# PCIE0_CORE_DBN_CFG_PCIE_CORE register map
Vendor: Texas Instruments
Peripheral module from a debugger description file (folder J722S).
Registers are 32-bit, read-write, reset 0x0 unless marked. A register's access mark holds for its fields unless they carry their own. Offsets are as the file gives them; lines under a group give offsets from that group; [hi:lo] are bit positions; {n}, {i} and the like mark numbered series; 'fields as' and 'values as' point back to an identical list; <NAME> marks a mode.

## PCIE0_CORE_DBN_CFG_PCIE_CORE (part 1 of 6)
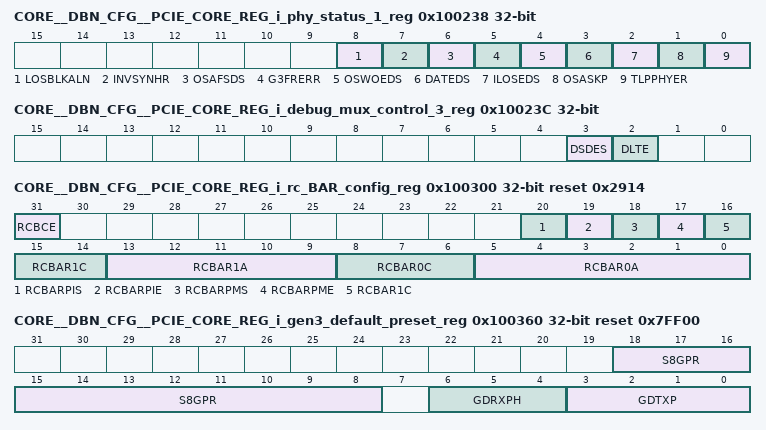
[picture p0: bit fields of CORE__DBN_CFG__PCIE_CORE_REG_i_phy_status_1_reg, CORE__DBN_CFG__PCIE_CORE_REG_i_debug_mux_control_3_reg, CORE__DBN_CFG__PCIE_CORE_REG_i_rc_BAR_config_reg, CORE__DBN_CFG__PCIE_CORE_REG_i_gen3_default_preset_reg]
0x100238 CORE__DBN_CFG__PCIE_CORE_REG_i_phy_status_1_reg access not given — This status register provides additional debug information about the PHY. Bits 8:0 provide information to debug Receiver Errors.
  [8] LOSBLKALN — This bit is set if the PHY Loses Block Alignment during data stream. This is detected based upon an unexpected PIPE_RX_VALID input deassertion during data stream. Write a 1 to clear this error. (access R/W1TC)
  [7] INVSYNHR — This bit is set if an invalid Sync Header is detected. 00 and 11 are Invalid Sync Headers. Write a 1 to clear this error. . (access R/W1TC)
  [6] OSAFSDS — This bit is set if an SDS is received after an SDS. This is a framing error. Write a 1 to clear this error. (access R/W1TC)
  [5] G3FRERR — This bit is set if a framing error is detected while receiving a TLP in Gen3. Example, if an invalid token is received in a data stream, this error is flagged. Write a 1 to clear this error. (access R/W1TC)
  [4] OSWOEDS — This bit is set if an Ordered Set Block is received without an EDS. This is a framing error. Write a 1 to clear this error. (access R/W1TC)
  [3] DATEDS — This bit is set if a Data Block is received after an EDS. Write a 1 to clear this error. (access R/W1TC)
  [2] ILOSEDS — The Valid OS blocks after an EDS are EIOS, EIEOS and SKP. If any other OS blocks are received after EDS, then it is a framing error and this bit is asserted. (access R/W1TC)
  [1] OSASKP — This bit indicates that an Ordered Set BLock was received immediately after a SKIP OS. This is a framing error. Write a 1 to clear this field. (access R/W1TC)
  [0] TLPPHYER — This bit indicates that a PHY Error was detected on the PIPE_RX_STATUS within a TLP. Write a 1 to clear this field. (access R/W1TC)
0x10023C CORE__DBN_CFG__PCIE_CORE_REG_i_debug_mux_control_3_reg
  [3] DSDES — Used to disable and enable Surprise Down Error status logging and by default it is enabled
  [2] DLTE — Used to disable and enable link training error logging and by default it is enabled
0x100300 CORE__DBN_CFG__PCIE_CORE_REG_i_rc_BAR_config_reg reset 0x2914 — The root complex side of the Controller contains two memory BARs that can be used for address-range checking of incoming requests from devices connected to it. The fields in this register determine the configuration of these BARs.
  [31] RCBCE — This bit must be set to 1 to enable BAR checking in the RC mode. When this bit is set to 0, the Controller will forward all incoming memory requests to the client logic without checking their address ranges.
  [20] RCBARPIS — Width of IO Base and Limit registers in type1 config space. 0=32 bits, 1=64bits
  [19] RCBARPIE — Enable for IO Base and Limit registers in type1 config space
  [18] RCBARPMS — Width of Prefetchable Memory Base and Limit registers in type1 config space. 0=32 bits, 1=64bits
  [17] RCBARPME — Enable for Prefetchable memory base and limit registers in type1 config space
  [16:14] RCBAR1C — Specifies the configuration of RC BAR1. The various encodings are: 000: Disabled 001: 32bit IO BAR 010-011: Reserved 100: 32bit memory BAR, non prefetchable 101: 32bit memory BAR, prefetchable 110-111: Reserved
  [13:9] RCBAR1A — This field specifies the aperture of the RC BAR 1. The encodings are: 0000 = 4, 00001 =8B,..... 1_1101 = 2G
  [8:6] RCBAR0C — Specifies the configuration of RC BAR0. The various encodings are: 000: Disabled 001: 32bit IO BAR 010-011: Reserved 100: 32bit memory BAR, non prefetchable 101: 32bit memory BAR, prefetchable 110: 64bit memory BAR, non prefetchable 111: 64bit memory BAR, prefetchable
  [5:0] RCBAR0A — This field specifies the aperture of the RC BAR 0. The encodings are: 0000 = 4, 00001 =8B,..... 01_1111 = 8G, ....10_0100 = 256G.
0x100360 CORE__DBN_CFG__PCIE_CORE_REG_i_gen3_default_preset_reg reset 0x7FF00 — This is register specifies the default transmitter preset and default receiver preset hint used by Controller for lanes that have not received EQ TS2s during Recovery.RcvrConfig LTSSM state
  [18:8] S8GPR — This register can be used to program the Presets that are supported by local Transmitter at 8Gbps. Default value of this register is determined by the SUPPORTED_PRESET strap input. Note: At 8.0 GT/s and 16.0 GT/s all preset values must be supported for Full swing signaling. Reduced swing signaling must implement presets #4, #1, #9, #5, #6, and #3.
  [6:4] GDRXPH — Default receiver preset hint value used for a lane that did not receive EQ TS2 in Recovery.RcvrCfg LTSSM state
  [3:0] GDTXP — Default transmitter preset value used for a lane that did not receive EQ TS2 in Recovery.RcvrCfg LTSSM state
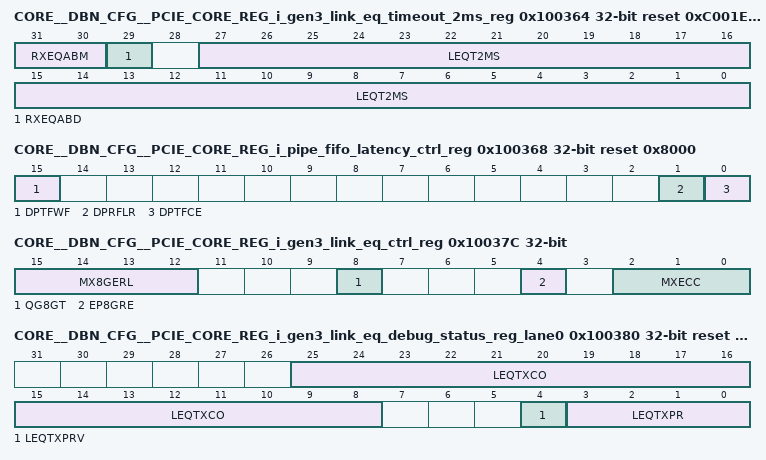
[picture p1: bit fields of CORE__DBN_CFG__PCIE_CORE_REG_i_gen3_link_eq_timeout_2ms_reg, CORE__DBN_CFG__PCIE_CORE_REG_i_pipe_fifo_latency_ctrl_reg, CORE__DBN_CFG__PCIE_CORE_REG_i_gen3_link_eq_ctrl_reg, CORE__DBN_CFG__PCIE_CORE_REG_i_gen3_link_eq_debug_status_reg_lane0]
0x100364 CORE__DBN_CFG__PCIE_CORE_REG_i_gen3_link_eq_timeout_2ms_reg reset 0xC001E848 — This register is used to tune the time spent for evaluation per TX Setting in Endpoint Phase 2 (RC Mode Phase 3) of GEN3 Link Equalization. The PCIe Spec defines a timeout of 2ms per TX setting and hence the default value for this register is set to 2ms. This can be tweaked based on the total number of iterations done and the time required for the PHY to respond with feedback for RXEQEVAL request. The total time taken in Endpoint Phase 2 (RC Mode Phase 3) must be less than 24 ms as defined by spec. Guideline: (Total Number of iterations)*(link_eq_timeout_2ms_reg + max time required for PHY to respond to RXEQEVAL) less than 24ms
  [31:30] RXEQABM — When a 24ms timeout occurs in the LTSSM Equalization Phase 2, the Controller aborts Equalization Phase 2 and transitions to Recovery.Rcvr.Lock. In this case, the RxEqEval output on the PIPE Interface will be de-asserted immediately [if it was asserted]. The RxEqInProgress output will stay high and waits for PhyStatus pulse. Controller implements a timer to select an upper limit to wait for this PhyStatus pulse during an abort to de-assert RxEqInProgress. 00: Wait for a maximum of 4 PIPE_PCLK period. 01: Wait for a maximum of 8 PIPE_PCLK period. 10: Wait for a maximum of 16 PIPE_PCLK period. 11: Disabled. Wait till PhyStatus Pulse is received. Note: This register is used only if RxEqEval was asserted when LTSSM 24ms timeout occured in Equalization.
  [29] RXEQABD — In an unexpected case where the PIPE_PCLK stops due to error in equalization, this bit can be set to de-couple RxEqInProgress from the rest of the equalization state machine. This bit should not be set for normal usage.
  [27:0] LEQT2MS — Time spent for evaluation per TX Setting in Endpoint Phase 2 [RC Mode Phase 3] of Link Equalization specified in multiples of 16ns. eg. the value 125000 will result in 125000*16ns = 2ms. Simulation with reduced time mode[PCIE_SIM define] will give a samller value of 300 as power on reset value.
0x100368 CORE__DBN_CFG__PCIE_CORE_REG_i_pipe_fifo_latency_ctrl_reg reset 0x8000 — This is register includes bits to control pipe fifo latency
  [15] DPTFWF — This bit can be used to prevent PIPE_TX_FIFO from reaching full during TX Electrical Idle. 0: During TX Electrical Idle, the PIPE_TX_FIFO is kept at half fill level by filtering the writes into the PIPE_TX_FIFO. 1: The PIPE_TX_FIFO write filtering logic is turned off. Default value of this bit is 1.
  [1] DPRFLR — 0: If FIFO empty is reached, the PIPE RX FIFO accumulates 2 entries before reading the FIFO again. 1: If FIFO empty is reached, the PIPE RX FIFO accumulates 6 entries before reading the FIFO again. This is to prevent FIFO from reaching empty again. Default value of this bit is 0, in order to reduce the latency through the PIPE RX FIFO.
  [0] DPTFCE — By default, if FIFO empty is reached, the PIPE TX FIFO accumulates 2 entries before reading the FIFO again. This is to prevent FIFO from reaching empty again. This bit must remain at 0 to allow the PIPE TX FIFO to recover effectively from a Empty condition.
0x10037C CORE__DBN_CFG__PCIE_CORE_REG_i_gen3_link_eq_ctrl_reg — This register is used to Control GEN3 Link Equalization Procedure.
  [15:12] MX8GERL — The number of 8GT/s Equalization Requests must be finite as per PCIe specification. This register can be used to program the maximum number of 8GT/s equalization requests automatically initiated by the Endpoint. 0000: Automatic 8GT/s Equalization Request Disabled. 0001: Automatic 8GT/s Equalization request limit is 1. 0010: Automatic 8GT/s Equalization request limit is 2. .... 1111: Automatic 8GT/s Equalization request limit is 15,
  [8] QG8GT — This bit can be used to program the Quiesce Guarantee bit of the TS2 in Recovery.Rcvr.Cfg state during 8GT/s Request Equalization.
  [4] EP8GRE — This bit can be used by Endpoint Device FW to request for 8GT/s Equalization redo. This bit can be set at any time after the Link is Up. Writing a 1 into this field results in the Controller to transition to Recovery. The Request Equalization bit in TS2 Ordered Sets will be set to 1 in Recovery.Rcvr.Cfg to request equalization at 8GTs. This bit is auto-cleared by the internal logic of the Controller after the re-training has been completed and link has reached the L0 state. This bit is also auto-cleared when not in Gen3 or Gen4. Device Firmware must wait for the bit to be clear before any subsequent retrain requests.
  [2:0] MXECC — Controls the number of consecutive RxEqEval iterations with direction change feedback of 00s before Equalization Convergence is inferred. 0 : Infer Convergence after 1 feedback of 000000 1 : Infer Convergence after 2 feedback of 000000 2 : Infer Convergence after 3 consecutive feedback of 000000 .. 7 : Infer Convergence after 8 consecutive feedback of 000000. Note: Each lane independently counts consecutive feedback of 000000. Note: Count is reset after a non-000000 feedback on each lane.
0x100380 CORE__DBN_CFG__PCIE_CORE_REG_i_gen3_link_eq_debug_status_reg_lane0 ro reset 0xB4004 — This register is used to reflect the negotiated TX Preset, Coefficients at the end of GEN3 Link Equalization. When the Controller is an Endpoint, this register reflects the Preset/Coefficients applied to the Endpoint Transmitter at the end of Gen3 Equalization Phase 3. When the Controller is an RC, this register reflects the Preset/Coefficients applied to the RC Transmitter at the end of Gen3 Equalization Phase 2.
  [25:8] LEQTXCO — TX Coefficients agreed upon for this lane. [25:20] : Post Cursor Coefficient [19:14] : Cursor Coefficient [13:8] : Pre-Cusror Coefficient
  [4] LEQTXPRV — TX Preset Valid Indicator. This bit is set when a TX Preset is received in TS1s with the use_preset bit set in Endpoint Mode Phase 3 or RC Mode Phase 2.
  [3:0] LEQTXPR — TX Preset agreed upon for this lane
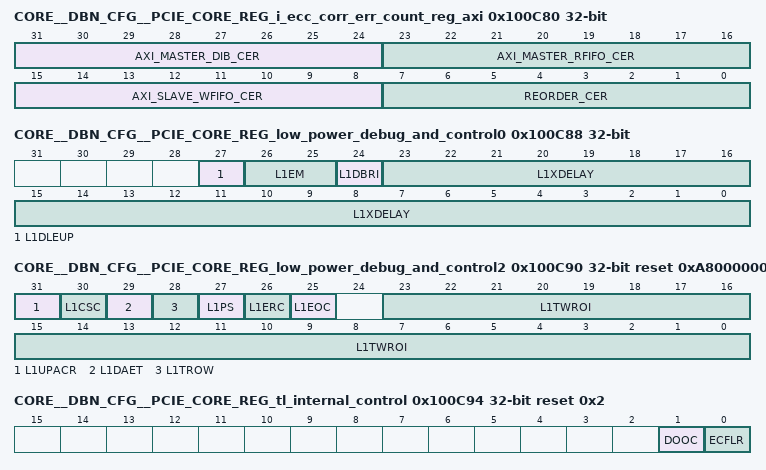
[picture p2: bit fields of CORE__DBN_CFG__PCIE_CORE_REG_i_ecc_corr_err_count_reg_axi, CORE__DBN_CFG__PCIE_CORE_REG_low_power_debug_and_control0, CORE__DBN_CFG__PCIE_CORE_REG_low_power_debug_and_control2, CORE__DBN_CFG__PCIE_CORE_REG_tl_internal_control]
0x100C80 CORE__DBN_CFG__PCIE_CORE_REG_i_ecc_corr_err_count_reg_axi access not given — This register contains the count of the number of ECC errors detected and corrected during reads from PCIe core AXI external RAMs.
  [31:24] AXI_MASTER_DIB_CER — Number of correctable errors detected while reading from the AXI Master Read Data interleave RAM. This is an 8-bit saturating counter that can be cleared by writing all 1s into it. (access R/W1TC)
  [23:16] AXI_MASTER_RFIFO_CER — Number of correctable errors detected while reading from the AXI master read fifo RAM. This is an 8-bit saturating counter that can be cleared by writing all 1's into it. (access R/W1TC)
  [15:8] AXI_SLAVE_WFIFO_CER — Number of correctable errors detected while reading from the AXI slave write fifo RAM. This is an 8-bit saturating counter that can be cleared by writing all 1's into it. (access R/W1TC)
  [7:0] REORDER_CER — Number of correctable errors detected while reading from the AXI slave reorder RAM. This is an 8-bit saturating counter that can be cleared by writing all 1's into it. (access R/W1TC)
0x100C88 CORE__DBN_CFG__PCIE_CORE_REG_low_power_debug_and_control0 access per field — This register controls internal behavior of controller for low power operations. Adjustment of this register is not required for normal operations.
  [27] L1DLEUP rw — Pending Tlps trigger a L1 exit by default. This includes internaly generated messages and internaly blocked TLPs. Setting this bit changes the default behavior. This is required only for debug purpose.
  [26:25] L1EM ro — This field shows the last entered L1 mode. This is useful for debug. bit 0 - Entry mode was ASPM. Bit 1 - Entry mode was PM. This is reset before any new L1 entry.
  [24] L1DBRI rw — Before entering L1, controller internally blocks all TLP and Register Request interface entering controller. interfaces are internally unblocked while exiting L1. This field control this behavior. '1' in this field makes the controler to do not perform any blocking to interfaces. '0' makes the controller behaves normaly. This is required only for debug purpose. Power shutoff feature has to be disabled while using this field.
  [23:0] L1XDELAY rw — Normaly L1 substate entry process is initiated immedaitely after LTSSM enters L1. A delay in micro-seconds can be given in this field to delay L1 substate entry process. This timeout has 0-1us margin of error. Power on reset value of this register can be adjusted by modifying the define den_db_LP_DBG_CTRL_L1_SUBSTATE_ENTRY_DELAY
0x100C8C CORE__DBN_CFG__PCIE_CORE_REG_low_power_debug_and_control1 ro — This register controls internal behavior of controller for low power operations. Adjustment of this register is not required for normal operations.
  [7:0] L1ER — This field shows the values of possible L1 or L1-substate exit triggers. This is useful for debug. this is captured during L1 or L1-substate exit process. this field is reset during L1 entry. 0 : CLIENT_REQ_EXIT_L1 asserted; 1 : Electrical Idle exit detected at link; 2 : New TLP request detected; 3 : Internal request to send TLP. This includes CFG completions. internal messages. INTx messages; 4 : Pending TX traffic available. This could be traffic from DMA and blocked traffic due to credits at AXI.; 5 : #CLKREQ assert detected; 6 : CLIENT_REQ_EXIT_L1_SUBSTATE asserted 7 : Reg Access request detected; Triggers #5,6,7 are valid only with L1-substate supported configs.
0x100C90 CORE__DBN_CFG__PCIE_CORE_REG_low_power_debug_and_control2 access per field reset 0xA8000000 — This register controls internal behavior of controller for low power operations. Adjustment of this register is not required for normal operations.
  [31] L1UPACR rw — Setting this field make the state machine to consider LP_CTRL_POWER_RECOVER_ACK as Client system recovery Complete ACK instead of the Controller power stable ACK. This field is ignored if LP_CTRL_BYPASS_ENABLE unset. If this field is set, L1-substate machines expect that the client system finishes power up of the controller within power_on time in the L1-substate capability register and Controller will be waiting in recovery state for ACK. This ensure that the PHY PLL lock and client system initialization goes on in parallel. Default value of this register can be set with the define:den_db_LP_DBG_CTRL_RECOVER_ACK_AS_CLIENT_RECOVER_ACK. Setting this field gives the best system performance.
  [30] L1CSC rw — L1-substate removes CORE_CLK. since the registers are implemented in core-clk, register access is not possible during L1-substate. If client can supply a slow clock to core[CORE_CLK] during L1-substates, APB/mgmt access is possible in L1.x. set this bit if client can supply slow clock to CORE_CLK when CLKREQ_IN_N is 1[de-asserted]. If this bit is set, Controller neither wake-up from L1 or generate error response for APB access during L1.x. Controller behavior is undefined if register write is performed while slow clock is supplied to core_clk. Recommended flow is to first exit from L1-substate and perform register writes. Power on reset value of this register can be adjusted by modifying the define den_db_LP_DBG_CTRL_CLIENT_SUPPLIES_SLOW_CLK_TO_CORE_DURING_L1
  [29] L1DAET rw — L1.x turns off clocks to the controller. Default behavior is made to exit L1.x if Register access request is present at register interface. Setting this bit disables this feature. If this bit is set and CLKREQ_IN_N is 1[de-asserted], Controller responds with ERROR response to APB requests. Client can use CLIENT_EXIT_L1_SUBSTATE pin to trigger L1.x exit if autonomous exit is disabled for register access. This bit is ignored if L1 substate is disabled. Power on reset value of this register can be adjusted by modifying the define den_db_LP_DBG_CTRL_DISABLE_AUTONOMOUS_L1_EXIT_ON_NEW_REG_REQ
  [28] L1TROW ro — This is a debug status field. '1' in this field indicates that a timeout has occured while waiting for RX path or OUTstanding packet IDLE conditions. This is cleared on new entry to L1.
  [27] L1PS rw — This field enabled power shutoff mechanism in L1.2 state. This field is ignored if L1.x is not enabled. Power on reset value of this register can be adjusted by modifying the define den_db_LP_DBG_CTRL_POWER_SHUTOFF_ENABLE
  [26] L1ERC rw — Enables waiting for RX path IDLE condition before entering L1.x. This checks that all packets from PCIE link has reached client side before entering L1.x. This only a tuning register. Not setting this regsiter will cause controller to enter L1.x to save power without checking this. controller will resume transferring RX data once it exit from L1.x state if RX buffers were not empty. This field is ignored if Power shutoff mechanism is enabled for L1.x and Controller will always check RX path idle condition before turning off internal power[with cpf flow]. If timeout is enabled, controller enters L1.x without internal power shutoff after timeout. This bit is ignored if L1 substate is disabled. Power on reset value of this register can be adjusted by modifying the define den_db_LP_DBG_CTRL_WAIT_FOR_RX_BUFFER_IDLE
  [25] L1EOC rw — Enable waiting for outstanding completions before entering L1.x. Outstanding packets expected from pcie link as well as from AXI side is checked. FOR HAL configurations client has to assert PREVENT_L1x_ENTRY signal to prevent L1x entry. This only a tuning register. Not setting this regsiter will cause controller to enter L1.x to save power without checking this. controller exit from L1.x as soon as it receives expected TLps. This field is ignored if Power shutoff mechanism is selected for L1.x and Controller will always wait for outstanding packets before turning off internal power[with cpf flow]. If timeout is enabled, controller enters L1.x without internal power shutoff after timeout. This bit is ignored if L1 substate is disabled. Power on reset value of this register can be adjusted by modifying the define den_db_LP_DBG_CTRL_WAIT_FOR_OUTSTANDING_CPLS
  [23:0] L1TWROI rw — This field enables a timeout mechanism while waiting for RX buffers and Outstanding Pkts before turning off power. Controller enters L1 substate after timeout. A value of 0x0 disables this timeout mechanism. Controller do not select internal power shutoff if it enters L1.x with this timeout. User can give timeout in micro-seconds using this register. This field is ignored if L1 substate is disabled. Power on reset value of this register can be adjusted by modifying the define den_db_LP_DBG_CTRL_RX_CPL_IDLE_CHECK_TIMEOUT
0x100C94 CORE__DBN_CFG__PCIE_CORE_REG_tl_internal_control reset 0x2 — This register controls internal behavior of Transaction layer of controller. Adjustment of this register is not required for normal operations.
  [1] DOOC — Ordering between outbound Completions and posted packets are maintainted in transaction layer. This is achieved by blocking Completions if required. Completions arrived after EOP of a posted packet are blocked till that posted packet is transmitted. This Ordering check is required to conform to the PCIe ordering rules. This ordering check can be disabled by setting this field. Power on reset value of this register can be adjusted by modifying the define den_db_TL_CTRL_DISABLE_OB_ORDERING_CHECK
  [0] ECFLR — By default controller ignores config request if a function is under going FLR. Setting this bit Makes the controller to respond with CRS response. Power on reset value of this register can be adjusted by modifying the define den_db_TL_CTRL_ENABLE_CRS_UNDER_FLR
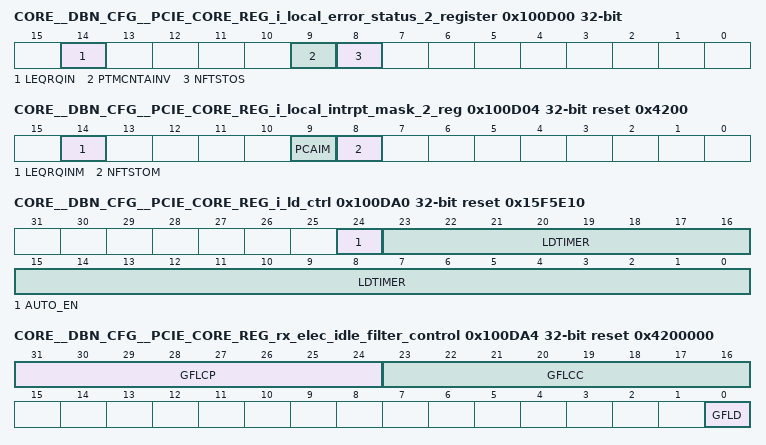
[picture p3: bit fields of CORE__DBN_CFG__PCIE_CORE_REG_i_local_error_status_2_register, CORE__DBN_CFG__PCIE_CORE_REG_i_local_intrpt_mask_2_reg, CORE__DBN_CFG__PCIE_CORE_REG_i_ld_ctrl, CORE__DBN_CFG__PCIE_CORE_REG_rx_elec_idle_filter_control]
0x100D00 CORE__DBN_CFG__PCIE_CORE_REG_i_local_error_status_2_register access not given — This is an extension of the Local Error and Status Register. This register contains the status of the various events, errors and abnormal conditions in the Controller. Any of the status bits can be reset by writing a 1 into the bit position. Unless masked by the setting of the Local Interrupt Mask 2 Register, the occurrence of any of these conditions causes the Controller to activate the LOCAL_INTERRUPT output.
  [14] LEQRQIN — EP Mode: Indicates that the Controller hardware detected a problem with equalization and automatically requested for equalization redo at the end of the equalization. Controller checks for problems in Recovery.Rcvr.Lock state by comparing the Tx Coefficients agreed at end of Eq Phase2 with the Tx Coefficients received in TS1s in Recovery.Rcvr.Lock state at the end of equalization. Any mismatch is detected and the Request Equalization bit is set in Recovery.Rcvg.Cfg. RC Mode: Indicates that the Controller received Equalization Request from downstream component. (access R/W1TC)
  [9] PTMCNTAINV — This status bit indicates that the Controller automatically invalidated PTM Context because of PCIe Link exit from L0 State. (access R/W1TC)
  [8] NFTSTOS — This status bit indicates that a NFTS Timeout occured. This could occur if the PHY failed to achieve lock on the receive data before the NFTS Timeout during Rx_L0s.FTS state. Local Firmware should consider increasing the advertized NFTS values if this event occurs. (access R/W1TC)
0x100D04 CORE__DBN_CFG__PCIE_CORE_REG_i_local_intrpt_mask_2_reg reset 0x4200 — This is an extension of the Local Interrupt Mask Register. This register contains a mask bit for each interrupting condition in local_error_status_2_register. Setting the bit to 1 prevents the corresponding condition in the Local Error Status 2 Register from activating the LOCAL_INTERRUPT output.
  [14] LEQRQINM — Mask for Link Equalization Request Interrupt.
  [9] PCAIM — Mask for PTM Context Auto Invalidated event.
  [8] NFTSTOM — Mask for NFTS Timeout.
0x100DA0 CORE__DBN_CFG__PCIE_CORE_REG_i_ld_ctrl reset 0x15F5E10 — This register is for the control of Link Down Indication Auto Reset behavior
  [24] AUTO_EN — This bit when set indicates that the link down indication auto reset is enabled
  [23:0] LDTIMER — This is a counter timeout value which triggers the internal logic to reset the link down indication bit in the AXI Configuration registers
0x100DA4 CORE__DBN_CFG__PCIE_CORE_REG_rx_elec_idle_filter_control reset 0x4200000 — This register controls the behavior of glitch filter on the pipe rx Electrical Idle signal from the PHY/PCS. Adjustment of this register is not required for normal operations.
  [31:24] GFLCP — This controls the glitch filter on PM Clock domain. This counter indicates the number of PM Clocks the glitch will be filtered out. The total delay of the glitch filter is calculated as [PM Clock Period * Number of PM Clocks] this delay should be same or close enough for both Core Clock[GFLCC] and PM Clock[GFLCP]
  [23:16] GFLCC — This controls the glitch filter on CORE Clock domain. This counter indicates the number of CORE Clocks the glitch will be filtered out. The total delay of the glitch filter is calculated as [CORE Clock Period * Number of CORE Clocks] this delay should be same or close enough for both CORE Clock[GFLCC] and PM Clock[GFLCP]
  [0] GFLD — By default controller enables glitch filter on all lanes. Setting this bit to one makes the controller to disable the glitch filter on that corresponding lanes in which the bit is set. When all bits are set to one the Glitch filter is completely bypassed, When any bit is zero glitch filter is enabled, and de-glitching is done only on the lanes that are set to zero
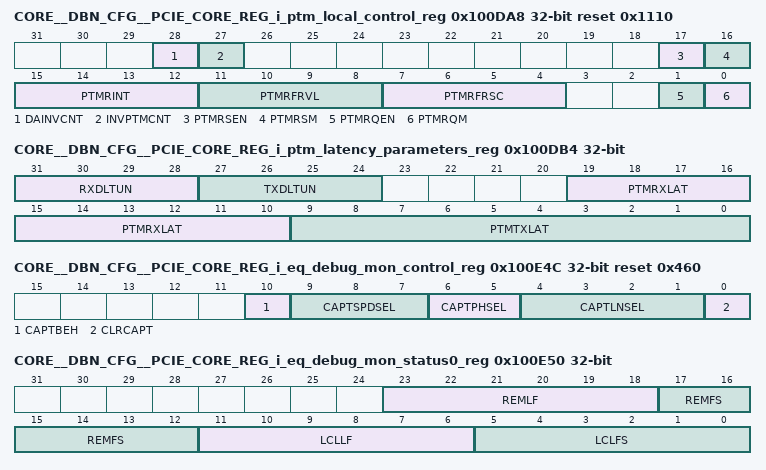
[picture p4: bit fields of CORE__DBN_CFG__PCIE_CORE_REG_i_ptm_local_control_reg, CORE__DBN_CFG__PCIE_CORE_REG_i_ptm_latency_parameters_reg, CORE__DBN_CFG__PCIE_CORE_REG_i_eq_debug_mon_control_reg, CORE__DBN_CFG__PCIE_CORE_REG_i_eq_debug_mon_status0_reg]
0x100DA8 CORE__DBN_CFG__PCIE_CORE_REG_i_ptm_local_control_reg access per field reset 0x1110 — The register bits to Control PTM operation are implemented in this Register.
  [28] DAINVCNT rw — By default, the Controller automatically invalidates PTM Context when the LTSSM exits L0 state. Client may disable this by writing a 1 to this register.
  [27] INVPTMCNT wo — Client Firmware may write a 1 to this bit in order to reset the PTM Context. This is a write-only bit. Controller internally clears this bit. Read from this bit returns 0. EP Mode: Resets the PTM Request State Machine. PTM Context is Cleared. RP Mode: Resets the PTM Response State Machine. PTM Context is Cleared.
  [17] PTMRSEN rw — EP Mode: Reserved RP Mode: This bit enables Controller [RP] to respond to the received PTM Requests. PTM Response/PTM ResponseD is determined by the PTM Response Mode bit. 1 : Controller automatically responds with Response/ResponseD messages. 0 : Controller does not respond for PTM Requests. [PTM Feature is Bypassed.]
  [16] PTMRSM rw — EP Mode: Reserved. RP Mode: This bit is used to control the number of PTM dialogs used during each PTM Master Time Request. 1 : Two Dialog Mode - Each PTM Context will have Response followed by ResponseD. Example: Dialog0: Request -> Response. Dialog1: Request -> ResponseD Dialog2: Request -> Response Dialog3: Request -> ResponseD 0 : Continuous Dialog Mode - Each PTM Context will have Only ResponseD. Example: Dialog0: Request -> Response. Dialog1: Request -> ResponseD Dialog2: Request -> ResponseD Dialog3: Request -> ResponseD
  [15:12] PTMRINT rw — EP Mode: In Single,Periodic Request Mode, this field is used to control the time interval [in us] between PTM Requests within a PTM Context. This represents the time the Requester State Machine waits in the WAIT_1US_STATE. 0001 - 1 0010 - 2 0011 - 3 0100 - 4 0101 - 5 0110 - 6 0111 - 7 1000 - 8 1001 - 9 .. 1111 - 15 This value is in [us]. RP Mode: Reserved.
  [11:8] PTMRFRVL rw — EP Mode: In Periodic Request Mode, this field is used to control the time interval [value] between successive PTM Context Refresh. This represents the time the Requester State Machine waits in the VALID_PTM_CONTEXT_STATE. 0001 - 1 0010 - 2 0011 - 3 0100 - 4 0101 - 5 0110 - 6 0111 - 7 1000 - 8 1001 - 9 1010 - 1111 Reserved This value is multiplied with the scale to determine the PTM Request Time Interval. RP Mode: Reserved.
  [7:4] PTMRFRSC rw — EP Mode: In Periodic Request Mode, this field is used to control the time interval [scale] between successive PTM Context Refresh. This represents the time the Requester State Machine waits in the VALID_PTM_CONTEXT_STATE. 0000 - 1 us 0001 - 10 us 0010 - 100 us 0011 - 1 ms 0100 - 10 ms 0101 - 100 ms 0110 - 1 s 0111 - 10 s 1000 - 100 s 1001 - 1111 - Reserved RP Mode: Reserved.
  [1] PTMRQEN rw — EP Mode: This enables Endpoint to request for PTM Master Time. 1 : PTM Requests are Enabled. In Single Request Mode, this bit is used to trigger PTM dialog to obtain PTM Master time exactly once. This bit is auto-cleared after the PTM Master time is obtained. In Periodic Request Mode, this bit enables periodic requests for PTM Master Time. This bit remains set till it is cleared by the EP local firmware. 0 : PTM Requests are Disabled. [PTM Feature is Bypassed.] User may disable PTM requests in the Controller and, if required, generate requests from Client Master Interface. RP Mode: Reserved.
  [0] PTMRQM rw — EP Mode: This bit controls the pattern of PTM Requests issued by the Endpoint. 0: Single Request Mode. 1: Periodic Request Mode. In Single Request Mode, Endpoint initiates one or two PTM Dialogs till the PTM Master Time is obtained. In Periodic Request Mode, Endpoint initiates PTM Dialogs and obtains PTM Master at periodic intervals. The period is programmable. RP Mode: Reserved.
0x100DAC CORE__DBN_CFG__PCIE_CORE_REG_i_ptm_local_status_reg ro — The status of PTM Dialog is reflected in this Register.
  [3:0] PTMCNST — Reflects the current status of the PTM Context. In EP Mode: 0000 - Invalid PTM Context 0001 - Dialog 1 PTM Request Sent 0011 - Dialog 1 PTM Response Received 0111 - Dialog 2 PTM Request Sent 1111 - Dialog 2 PTM ResponseD Received and PTM Context Valid In RP Mode: 0000 - Invalid PTM Context 0001 - Dialog 1 PTM Request Received 0011 - Dialog 1 PTM Response Sent 0111 - Dialog 2 PTM Request Received 1111 - Dialog 2 PTM ResponseD Sent and PTM Context Valid
0x100DB0 CORE__DBN_CFG__PCIE_CORE_REG_i_ptm_latency_parameters_index_reg — The latency parameters of the PHY may be different at different speeds of operation. Hence, the Controller implements multiple instances of the PTM Latency Parameters Register, one instance for each speed of operation. This register is used to select the speed prior to programming the speed-specific delay parameter registers.
  [3:0] PTMLATIN — This is used by FW to select the speed for which the Latency parameters are to be programmed. FW is required to set this to each of the supported speeds and program the corresponding latency parameters in the PTM Latency Parameters Register. 0000 - Gen1 Speed Select 0001 - Gen2 Speed Select 0010 - Gen3 Speed Select 0011 - Gen4 Speed Select Others - Reserved
0x100DB4 CORE__DBN_CFG__PCIE_CORE_REG_i_ptm_latency_parameters_reg — This register is used to define the PHY specific delay parameters. This register also implements control bits to fine-tune timestamps that are captured by the Controller. Internally, one instance of this register is implemented for each of the speeds supported by the Controller and is indexed by the PTM Latency Parameters Index Register.
  [31:28] RXDLTUN — In EP Mode: This field can be used to add a fixed offset to the captured timestamps t4 and t4_tick. In RP Mode: This field can be used to add a fixed offset to the captured timestamps t2 and t2_tick. Encoding: 0000: + 0 ns 0001: + 1ns 0010: + 2ns .... 1111: + 15ns Separate value can be programmed for each supported speed of operation. The speed of operation must first be programmed in the PTM Latency Parameters Index Register and then the corresponding value be programmed into this register.
  [27:24] TXDLTUN — In EP Mode: This field can be used to add a fixed offset to the captured timestamps t1 and t1_tick. In RP Mode: This field can be used to add a fixed offset to the captured timestamps t3 and t3_tick. Encoding: 0000: + 0 ns 0001: + 1ns 0010: + 2ns .... 1111: + 15ns Separate value can be programmed for each supported speed of operation. The speed of operation must first be programmed in the PTM Latency Parameters Index Register and then the corresponding value be programmed into this register.
  [19:10] PTMRXLAT — This field should be programmed with the parameter Receive Latency in [ns] from the PHY Datasheet. Separate value can be programmed for each supported speed of operation. The speed of operation must first be programmed in the PTM Latency Parameters Index Register and then the corresponding latency be programmed into this register.
  [9:0] PTMTXLAT — This field should be programmed with the parameter Transmit Latency in [ns] from the PHY Datasheet. Separate value can be programmed for each supported speed of operation. The speed of operation must first be programmed in the PTM Latency Parameters Index Register and then the corresponding latency be programmed into this register.
0x100DB8 CORE__DBN_CFG__PCIE_CORE_REG_i_ptm_context_1_reg ro — PTM Context 1 Register.
  [31:0] PTMT1T2 — EP Mode : Represents the lower 32-bits of timestamp t1 in [ns] as recorded by Endpoint. RP Mode : Represents the lower 32-bits of timestamp t2 in [ns] as recorded by RP.
0x100DBC CORE__DBN_CFG__PCIE_CORE_REG_i_ptm_context_2_reg ro — PTM Context 2 Register.
  [31:0] PTMT1T2U — EP Mode : Represents the upper 32-bits of timestamp t1 in [ns] as recorded by Endpoint. RP Mode : Represents the upper 32-bits of timestamp t2 in [ns] as recorded by RP.
0x100DC0 CORE__DBN_CFG__PCIE_CORE_REG_i_ptm_context_3_reg ro — PTM Context 3 Register.
  [31:0] PTMT4T3 — EP Mode : Represents the lower 32-bits of timestamp t4 in [ns] as recorded by Endpoint. RP Mode : Represents the lower 32-bits of timestamp t3 in [ns] as recorded by RP.
0x100DC4 CORE__DBN_CFG__PCIE_CORE_REG_i_ptm_context_4_reg ro — PTM Context 4 Register.
  [31:0] PTMT4T3U — EP Mode : Represents the upper 32-bits of timestamp t4 in [ns] as recorded by Endpoint. RP Mode : Represents the upper 32-bits of timestamp t3 in [ns] as recorded by RP.
0x100DC8 CORE__DBN_CFG__PCIE_CORE_REG_i_ptm_context_5_reg ro — PTM Context 5 Register.
  [31:0] PTMT1KT2K — EP Mode : Represents the lower 32-bits of timestamp t1_tick in [ns] as recorded by Endpoint. RP Mode : Represents the lower 32-bits of timestamp t2_tick in [ns] as recorded by RP.
0x100DCC CORE__DBN_CFG__PCIE_CORE_REG_i_ptm_context_6_reg ro — PTM Context 6 Register.
  [31:0] PTMT1KT2KU — EP Mode : Represents the upper 32-bits of timestamp t1_tick in [ns] as recorded by Endpoint. RP Mode : Represents the upper 32-bits of timestamp t2_tick in [ns] as recorded by RP.
0x100DD0 CORE__DBN_CFG__PCIE_CORE_REG_i_ptm_context_7_reg ro — PTM Context 7 Register.
  [31:0] PTMT4KT3K — EP Mode : Represents the lower 32-bits of timestamp t4_tick in [ns] as recorded by Endpoint. RP Mode : Represents the lower 32-bits of timestamp t3_tick in [ns] as recorded by RP.
0x100DD4 CORE__DBN_CFG__PCIE_CORE_REG_i_ptm_context_8_reg ro — PTM Context 8 Register.
  [31:0] PTMT4KT3KU — EP Mode : Represents the upper 32-bits of timestamp t4_tick in [ns] as recorded by Endpoint. RP Mode : Represents the upper 32-bits of timestamp t3_tick in [ns] as recorded by RP.
0x100DD8 CORE__DBN_CFG__PCIE_CORE_REG_i_ptm_context_9_reg ro — PTM Context 9 Register.
  [31:0] PTMT3MT2 — Propagation Delay. EP Mode : Represents the Propagation Delay [t3 - t2] in [ns] as received in ResponseD Message by Endpoint. RP Mode - Reserved.
0x100DDC CORE__DBN_CFG__PCIE_CORE_REG_i_ptm_context_10_reg ro — PTM Context 10 Register.
  [31:0] PTMMSTT1T — EP Mode - Represents the lower 32-bits of PTM Master Time at timestamp t1_tick in [ns] as computed by Endpoint. RP Mode - Reserved.
0x100DE0 CORE__DBN_CFG__PCIE_CORE_REG_i_ptm_context_11_reg ro — PTM Context 11 Register.
  [31:0] PTMMSTT1TU — EP Mode - Represents the upper 32-bits of PTM Master Time at timestamp t1_tick in [ns] as computed by Endpoint. RP Mode - Reserved.
0x100E4C CORE__DBN_CFG__PCIE_CORE_REG_i_eq_debug_mon_control_reg access per field reset 0x460 — The register bits to Control EQ debug Monitor operation are implemented in this Register.
  [10] CAPTBEH ro — If this is set , the first 64 equalization info events are captured else the last 64 events are captured
  [9:7] CAPTSPDSEL rw — Selects the Link Speed at which capture is to be done 000 : Any speed, 001 : Gen 3, 010 : Gen 4, 100 : Gen 5
  [6:5] CAPTPHSEL rw — Selects the Equalization Phase when capture is to be done 01 : Phase 2, 10 : Phase 3, 11 : Phase 2 and 3
  [4:1] CAPTLNSEL rw — Selects the Lane whose Equalization Debug information is to be captured.Please note,this signifies the physical lane number.
  [0] CLRCAPT rw — Setting this bit clears all captured information in the EQ Debug Status Registers. If it is unset then capture is allowed in status registers.
0x100E50 CORE__DBN_CFG__PCIE_CORE_REG_i_eq_debug_mon_status0_reg ro — Both the Local and Remote EQ FS and LF values are captured in this Register.
  [23:18] REMLF — Remote PHY's LF Value Of the Lane and Speed Selected.
  [17:12] REMFS — Remote PHY's FS Value Of the Lane and Speed Selected.
  [11:6] LCLLF — Local PHY's LF Value Of the Lane and Speed Selected.
  [5:0] LCLFS — Local PHY's FS Value Of the Lane and Speed Selected.
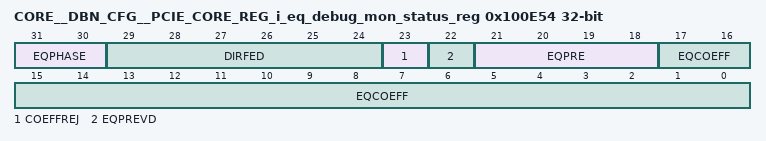
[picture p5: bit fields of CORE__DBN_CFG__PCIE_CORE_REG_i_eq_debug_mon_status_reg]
0x100E54 CORE__DBN_CFG__PCIE_CORE_REG_i_eq_debug_mon_status_reg ro — All the Dynamic Equalization information is captured in this Register.This is implemented using a synchronous FIFO which stores all the captured events as sepereate 32 bit entries.The define den_db_EQ_DEBUG_FIFO_NUM_ENTRIES in defines.h controls the number of entries of the FIFO.Every read increments the read pointer and the client must store the data read.The FIFO can be cleared using the 'Clear all Capture bit in the EQ Debug Monitor Control Register.
  [31:30] EQPHASE — Equalization Phase during Capture 00 : Phase 0, 01 : Phase 1, 10 : Phase 2, 11 : Phase 3
  [29:24] DIRFED — EP Ph2/RC Ph3: Stores Direction Change Feedback or Preset feedback Transmitted to Remote Device. Bit-22, EQPREVD, indicates if this is a Preset feedback or Direction Change Feedback. EP Ph3/RC Ph2: Reserved
  [23] COEFFREJ — Phase0: Set to '1' if an unsupported preset is received in Phase0. Phase1: Set to '0' since no reject in phase1. EP Ph2/RC Ph3: Indicates Reject by the Remote end device. This bit indicates that the current Coefficient or Preset was rejected by the remote end device. EP Ph3/RC Ph2: Indicates that Controller Rejected the received settings to Remote Device in the TX TS1/TS2. This Reject indicates the current Coefficients or Preset received from Remote Device are rejected
  [22] EQPREVD — 1: Preset Valid, Indicates [21:18] is valid. Phase0: Set to '1' to indicate that the intial Local Preset is Valid. Phase1: Set to '1' to indicate that the advertised Remote Preset is Valid. EP Ph2/RC Ph3: Set to 1 if controller provide preset feedback and to 0 for coefficient feedback. EP Ph3/RC Ph2: Reflects the use preset bit received from the remote end.
  [21:18] EQPRE — Phase0: Stores Initial Local TX Preset received in Phase0. Phase1: Stores Initial Remote Preset advertised in Phase1. EP Ph2/RC Phase3: Stores Current Preset of the Remote Device. EP Ph3/RC Phase2: Stores Preset Received from Remote Device.
  [17:0] EQCOEFF — Phase0: Stores Initial Local TX Coefficients mapped from Initial Preset. Phase1: Stores Initial Remote Coefficients advertised in Phase1. [Cp, LF, FS] , EP Ph2/RC Phase3: Stores Current Coefficients of the Remote Device. EP Ph3/RC Phase2: Stores Coefficients Received from Remote Device.
